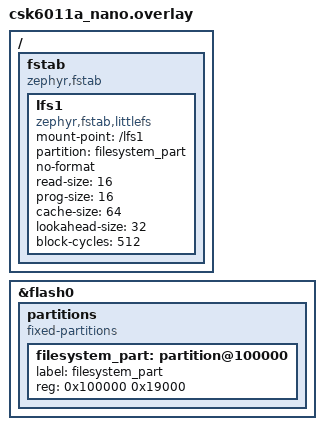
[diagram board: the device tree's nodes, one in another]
/*
 * SPDX-License-Identifier: Apache-2.0
 */
/delete-node/ &storage_partition;

/ {
	fstab {
		compatible = "zephyr,fstab";
		lfs1: lfs1 {
			compatible = "zephyr,fstab,littlefs";
			mount-point = "/lfs1";
			partition = <&filesystem_part>;
			no-format;
			read-size = <16>;
			prog-size = <16>;
			cache-size = <64>;
			lookahead-size = <32>;
			block-cycles = <512>;
		};
	};

};

&flash0 {
	partitions {
		compatible = "fixed-partitions";
		#address-cells = <1>;
		#size-cells = <1>;
		filesystem_part: partition@100000 {
			label = "filesystem_part";
			reg = <0x100000 0x19000>;
		};
	};
};
